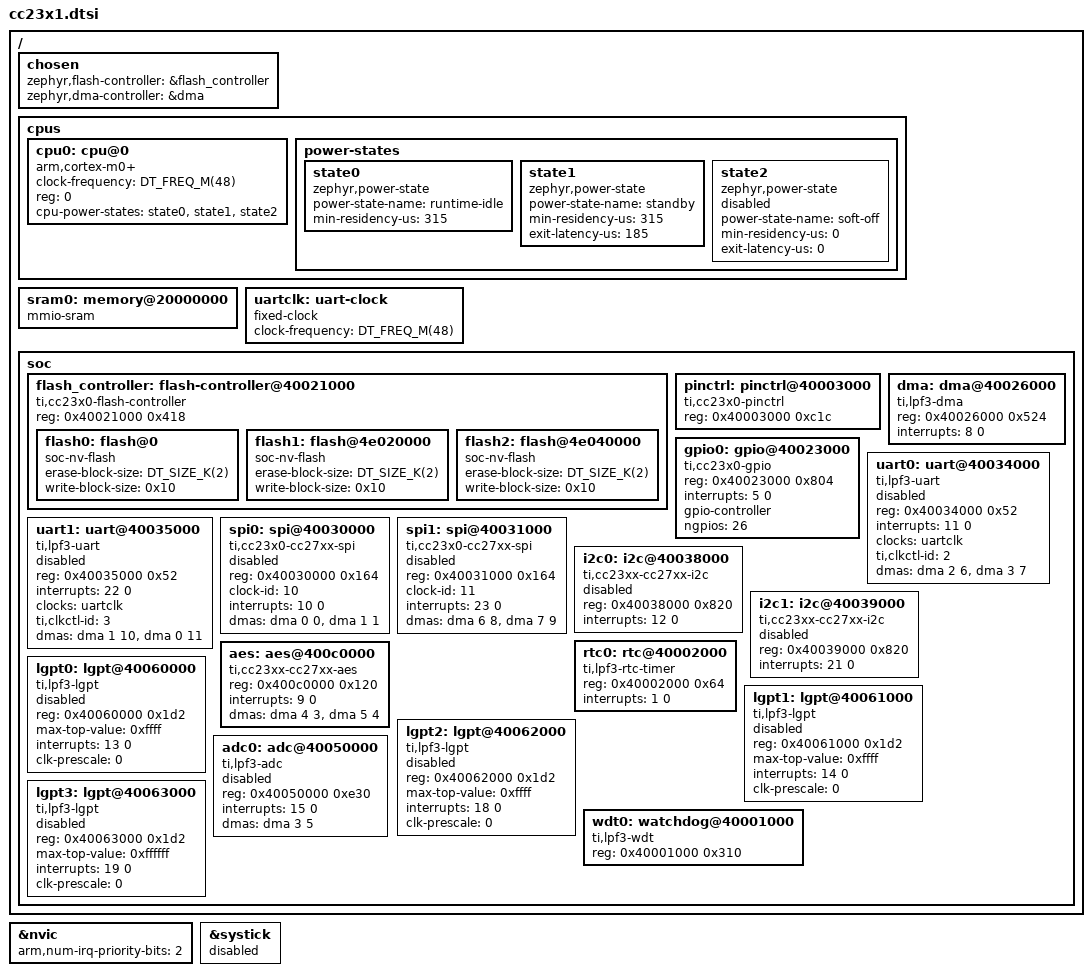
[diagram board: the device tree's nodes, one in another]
/*
 * Copyright (c) 2026 Texas Instruments Incorporated
 *
 * SPDX-License-Identifier: Apache-2.0
 */

#include <arm/armv6-m.dtsi>
#include <freq.h>

/ {
	chosen {
		zephyr,flash-controller = &flash_controller;
		zephyr,dma-controller = &dma;
	};

	cpus {
		#address-cells = <1>;
		#size-cells = <0>;

		cpu0: cpu@0 {
			device_type = "cpu";
			compatible = "arm,cortex-m0+";
			clock-frequency = <DT_FREQ_M(48)>;
			reg = <0>;
			cpu-power-states = <&state0 &state1 &state2>;
		};

		power-states {
			state0: state0 {
				compatible = "zephyr,power-state";
				power-state-name = "runtime-idle";
				min-residency-us = <315>;
			};

			state1: state1 {
				compatible = "zephyr,power-state";
				power-state-name = "standby";
				min-residency-us = <315>;
				exit-latency-us = <185>;
			};

			/* PM_STATE_SOFT_OFF can be entered only by calling pm_state_force */
			state2: state2 {
				compatible = "zephyr,power-state";
				power-state-name = "soft-off";
				min-residency-us = <0>;
				exit-latency-us = <0>;
				status = "disabled";
			};
		};
	};

	sram0: memory@20000000 {
		compatible = "mmio-sram";
	};

	uartclk: uart-clock {
		compatible = "fixed-clock";
		clock-frequency = <DT_FREQ_M(48)>;
		#clock-cells = <0>;
	};

	soc {
		flash_controller: flash-controller@40021000 {
			compatible = "ti,cc23x0-flash-controller";
			reg = <0x40021000 0x418>;
			#address-cells = <1>;
			#size-cells = <1>;

			/* Main flash sector */
			flash0: flash@0 {
				compatible = "soc-nv-flash";
				erase-block-size = <DT_SIZE_K(2)>;
				write-block-size = <0x10>;
			};

			/* CCFG flash sector */
			flash1: flash@4e020000 {
				compatible = "soc-nv-flash";
				erase-block-size = <DT_SIZE_K(2)>;
				write-block-size = <0x10>;
			};

			/* SCFG flash sector */
			flash2: flash@4e040000 {
				compatible = "soc-nv-flash";
				erase-block-size = <DT_SIZE_K(2)>;
				write-block-size = <0x10>;
			};
		};

		pinctrl: pinctrl@40003000 {
			compatible = "ti,cc23x0-pinctrl";
			reg = <0x40003000 0xc1c>;
		};

		dma: dma@40026000 {
			compatible = "ti,lpf3-dma";
			reg = <0x40026000 0x524>;
			interrupts = <8 0>;
			#dma-cells = <2>;
			status = "okay";
		};

		gpio0: gpio@40023000 {
			compatible = "ti,cc23x0-gpio";
			reg = <0x40023000 0x804>;
			interrupts = <5 0>;	/* GPIO combined on CPUIRQ5 */
			status = "okay";
			gpio-controller;
			#gpio-cells = <2>;	/* Pin (ID), and flags */
			ngpios = <26>;		/* Only [DIO0, DIO25] are bonded out */
		};

		uart0: uart@40034000 {
			compatible = "ti,lpf3-uart";
			reg = <0x40034000 0x52>;
			interrupts = <11 0>;
			clocks = <&uartclk>;
			ti,clkctl-id = <2>; /* CLKCTL_UART0 */
			dmas = <&dma 2 6>, <&dma 3 7>;
			dma-names = "tx", "rx";
			status = "disabled";
		};

		uart1: uart@40035000 {
			compatible = "ti,lpf3-uart";
			reg = <0x40035000 0x52>;
			interrupts = <22 0>;
			clocks = <&uartclk>;
			ti,clkctl-id = <3>; /* CLKCTL_UART1 */
			dmas = <&dma 1 10>, <&dma 0 11>;
			dma-names = "tx", "rx";
			status = "disabled";
		};

		spi0: spi@40030000 {
			compatible = "ti,cc23x0-cc27xx-spi";
			#address-cells = <1>;
			#size-cells = <0>;
			reg = <0x40030000 0x164>;
			clock-id = <10>; /* CLKCTL_SPI0 */
			interrupts = <10 0>;
			dmas = <&dma 0 0>, <&dma 1 1>;
			dma-names = "tx", "rx";
			status = "disabled";
		};

		spi1: spi@40031000 {
			compatible = "ti,cc23x0-cc27xx-spi";
			#address-cells = <1>;
			#size-cells = <0>;
			reg = <0x40031000 0x164>;
			clock-id = <11>; /* CLKCTL_SPI1 */
			interrupts = <23 0>;
			dmas = <&dma 6 8>, <&dma 7 9>;
			dma-names = "tx", "rx";
			status = "disabled";
		};

		i2c0: i2c@40038000 {
			compatible = "ti,cc23xx-cc27xx-i2c";
			#address-cells = <1>;
			#size-cells = <0>;
			reg = <0x40038000 0x820>;
			interrupts = <12 0>;
			status = "disabled";
		};

		i2c1: i2c@40039000 {
			compatible = "ti,cc23xx-cc27xx-i2c";
			#address-cells = <1>;
			#size-cells = <0>;
			reg = <0x40039000 0x820>;
			interrupts = <21 0>;
			status = "disabled";
		};

		aes: aes@400c0000 {
			compatible = "ti,cc23xx-cc27xx-aes";
			reg = <0x400c0000 0x120>;
			interrupts = <9 0>;
			dmas = <&dma 4 3>, <&dma 5 4>;
			dma-names = "cha", "chb";
			status = "okay";
		};

		rtc0: rtc@40002000 {
			compatible = "ti,lpf3-rtc-timer";
			reg = <0x40002000 0x64>;
			/* RTC interrupt signal is mapped to IRQ1. This interrupt line is not a
			 * dedicated interrupt line for the RTC peripheral.
			 */
			interrupts = <1 0>;
			status = "okay";
		};

		lgpt0: lgpt@40060000 {
			compatible = "ti,lpf3-lgpt";
			reg = <0x40060000 0x1d2>;
			max-top-value = <0xffff>;
			interrupts = <13 0>;
			clk-prescale = <0>;
			status = "disabled";
		};

		lgpt1: lgpt@40061000 {
			compatible = "ti,lpf3-lgpt";
			reg = <0x40061000 0x1d2>;
			max-top-value = <0xffff>;
			interrupts = <14 0>;
			clk-prescale = <0>;
			status = "disabled";
		};

		lgpt2: lgpt@40062000 {
			compatible = "ti,lpf3-lgpt";
			reg = <0x40062000 0x1d2>;
			max-top-value = <0xffff>;
			interrupts = <18 0>;
			clk-prescale = <0>;
			status = "disabled";
		};

		lgpt3: lgpt@40063000 {
			compatible = "ti,lpf3-lgpt";
			reg = <0x40063000 0x1d2>;
			max-top-value = <0xffffff>;
			interrupts = <19 0>;
			clk-prescale = <0>;
			status = "disabled";
		};

		adc0: adc@40050000 {
			compatible = "ti,lpf3-adc";
			reg = <0x40050000 0xe30>;
			interrupts = <15 0>;
			#io-channel-cells = <1>;
			dmas = <&dma 3 5>;
			dma-names = "dma";
			status = "disabled";
		};

		wdt0: watchdog@40001000 {
			compatible = "ti,lpf3-wdt";
			reg = <0x40001000 0x310>;
			status = "okay";
		};
	};
};

&nvic {
	arm,num-irq-priority-bits = <2>; /* Interrupt levels are 0-192 in steps of 64 */
};

&systick {
	status = "disabled";
};
